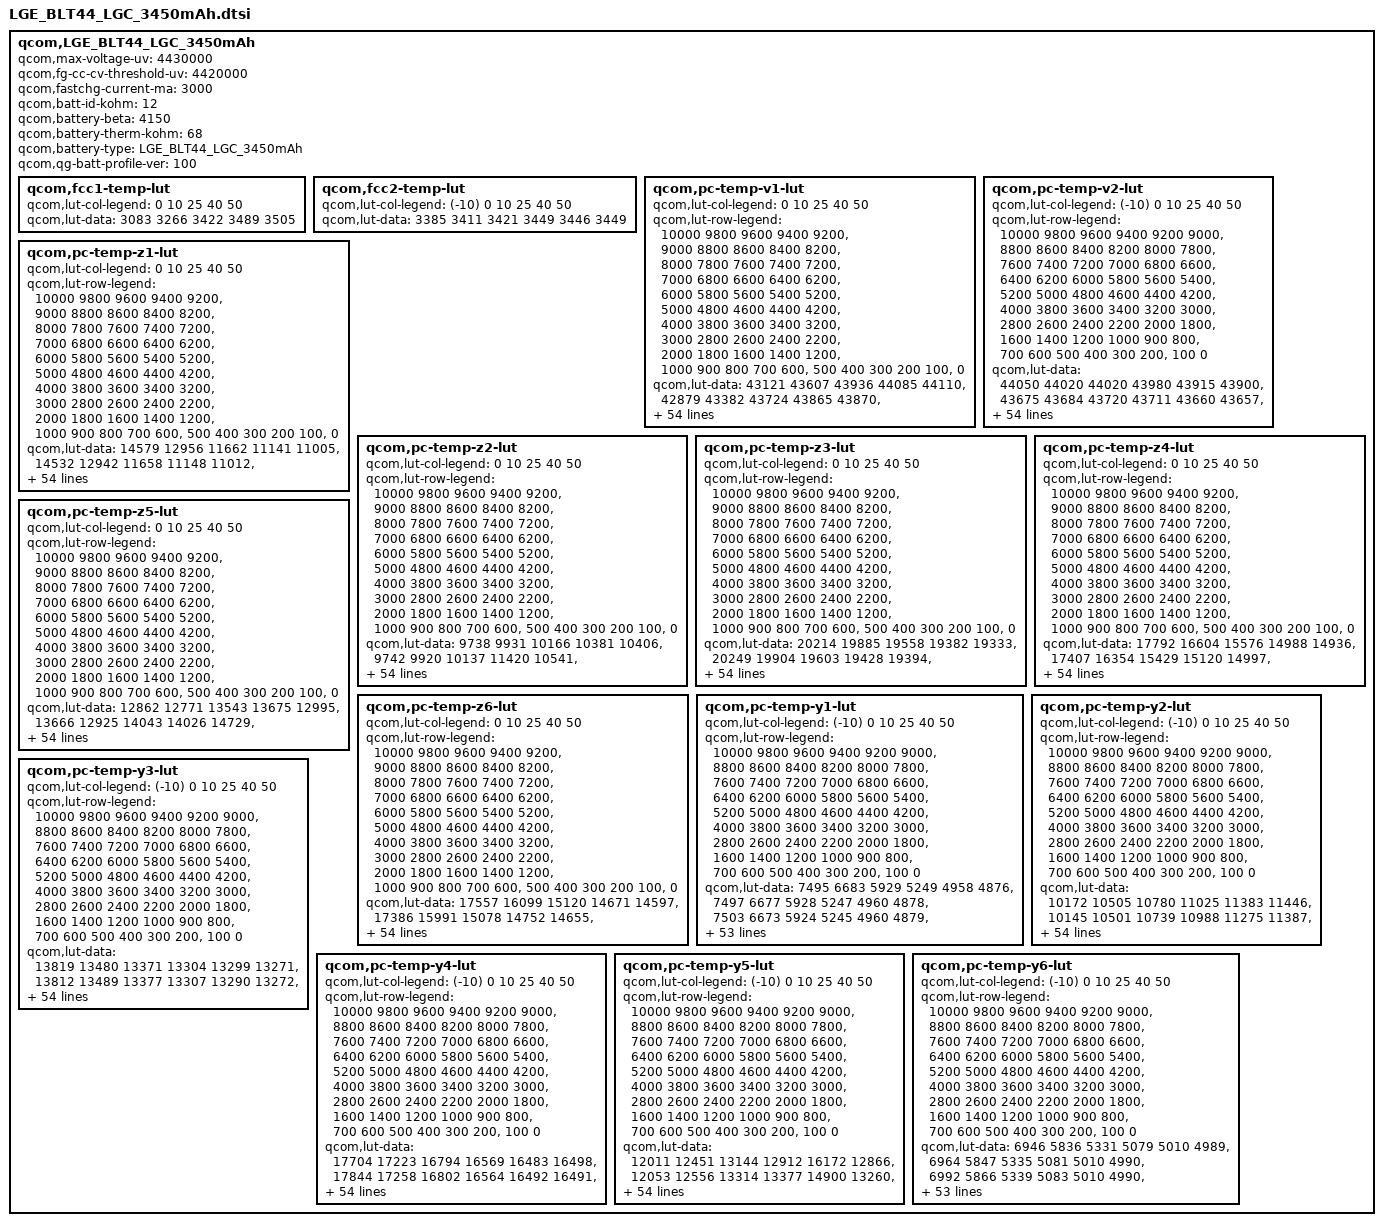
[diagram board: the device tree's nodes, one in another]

qcom,LGE_BLT44_LGC_3450mAh {
    /* 3748128_LGE_CV7ASlgc_3450mAh_averaged_MasterSlave_Dec13th2018 */
    qcom,max-voltage-uv = <4430000>;
    qcom,fg-cc-cv-threshold-uv = <4420000>;
    qcom,fastchg-current-ma = <3000>;
    qcom,batt-id-kohm = <12>;
    qcom,battery-beta = <4150>;
    qcom,battery-therm-kohm = <68>;
    qcom,battery-type = "LGE_BLT44_LGC_3450mAh";
    qcom,qg-batt-profile-ver = <100>;

	qcom,fcc1-temp-lut {
		qcom,lut-col-legend = <0 10 25 40 50>;
		qcom,lut-data = <3083 3266 3422 3489 3505>;
	};

	qcom,fcc2-temp-lut {
		qcom,lut-col-legend = <(-10) 0 10 25 40 50>;
		qcom,lut-data = <3385 3411 3421 3449 3446 3449>;
	};

	qcom,pc-temp-v1-lut {
		qcom,lut-col-legend = <0 10 25 40 50>;
		qcom,lut-row-legend = <10000 9800 9600 9400 9200>,
			<9000 8800 8600 8400 8200>,
			<8000 7800 7600 7400 7200>,
			<7000 6800 6600 6400 6200>,
			<6000 5800 5600 5400 5200>,
			<5000 4800 4600 4400 4200>,
			<4000 3800 3600 3400 3200>,
			<3000 2800 2600 2400 2200>,
			<2000 1800 1600 1400 1200>,
			<1000 900 800 700 600>,
			<500 400 300 200 100>,
			<0>;
		qcom,lut-data = <43121 43607 43936 44085 44110>,
			<42879 43382 43724 43865 43870>,
			<42643 43154 43503 43648 43652>,
			<42412 42922 43274 43426 43436>,
			<42188 42686 43038 43196 43211>,
			<41967 42449 42798 42960 42981>,
			<41752 42217 42557 42721 42746>,
			<41540 41986 42315 42479 42505>,
			<41334 41761 42077 42236 42262>,
			<41135 41539 41840 41994 42022>,
			<40941 41323 41608 41754 41784>,
			<40748 41113 41379 41520 41549>,
			<40548 40910 41156 41291 41318>,
			<40354 40712 40945 41068 41091>,
			<40176 40509 40740 40851 40872>,
			<40014 40309 40540 40640 40659>,
			<39863 40125 40341 40438 40454>,
			<39726 39958 40151 40241 40255>,
			<39598 39800 39976 40055 40066>,
			<39479 39647 39813 39892 39896>,
			<39364 39501 39648 39729 39730>,
			<39255 39358 39483 39524 39530>,
			<39150 39219 39309 39266 39285>,
			<39051 39082 39088 39047 39069>,
			<38956 38942 38827 38888 38907>,
			<38866 38791 38657 38755 38768>,
			<38781 38654 38574 38639 38642>,
			<38700 38549 38512 38537 38528>,
			<38622 38461 38446 38443 38425>,
			<38546 38390 38383 38351 38331>,
			<38475 38334 38321 38267 38245>,
			<38413 38287 38258 38195 38169>,
			<38359 38245 38198 38132 38100>,
			<38307 38209 38147 38075 38037>,
			<38261 38174 38102 38027 37985>,
			<38218 38139 38058 37981 37932>,
			<38171 38103 38018 37929 37865>,
			<38116 38058 37975 37874 37788>,
			<38053 37992 37910 37806 37710>,
			<37977 37908 37813 37720 37635>,
			<37874 37806 37702 37619 37550>,
			<37751 37675 37579 37504 37435>,
			<37602 37529 37442 37371 37295>,
			<37464 37366 37280 37209 37132>,
			<37359 37230 37146 37066 36992>,
			<37247 37147 37066 36984 36917>,
			<37200 37120 37044 36965 36902>,
			<37158 37096 37027 36952 36889>,
			<37112 37062 37003 36934 36870>,
			<37018 36997 36955 36878 36806>,
			<36768 36761 36703 36613 36514>,
			<36320 36298 36263 36164 36068>,
			<35731 35710 35682 35567 35480>,
			<34928 34890 34886 34739 34672>,
			<33556 33548 33630 33472 33430>,
			<30000 30000 30000 30000 30000>;
	};

	qcom,pc-temp-v2-lut {
		qcom,lut-col-legend = <(-10) 0 10 25 40 50>;
		qcom,lut-row-legend = <10000 9800 9600 9400 9200 9000>,
			<8800 8600 8400 8200 8000 7800>,
			<7600 7400 7200 7000 6800 6600>,
			<6400 6200 6000 5800 5600 5400>,
			<5200 5000 4800 4600 4400 4200>,
			<4000 3800 3600 3400 3200 3000>,
			<2800 2600 2400 2200 2000 1800>,
			<1600 1400 1200 1000 900 800>,
			<700 600 500 400 300 200>,
			<100 0>;
		qcom,lut-data = <44050 44020 44020 43980 43915 43900>,
			<43675 43684 43720 43711 43660 43657>,
			<43333 43371 43436 43451 43412 43419>,
			<43030 43086 43170 43204 43171 43184>,
			<42762 42828 42922 42968 42938 42955>,
			<42509 42577 42679 42733 42705 42723>,
			<42267 42318 42431 42491 42467 42486>,
			<42032 42061 42185 42248 42228 42246>,
			<41767 41818 41943 42009 41991 42009>,
			<41451 41587 41705 41772 41754 41772>,
			<41159 41360 41472 41539 41522 41540>,
			<40959 41133 41245 41308 41294 41313>,
			<40796 40907 41022 41082 41070 41090>,
			<40581 40681 40808 40865 40853 40874>,
			<40248 40455 40603 40656 40642 40662>,
			<39903 40229 40399 40452 40438 40457>,
			<39647 39997 40196 40249 40240 40258>,
			<39430 39764 39992 40050 40050 40066>,
			<39226 39549 39785 39866 39871 39886>,
			<39031 39349 39570 39699 39708 39721>,
			<38839 39159 39357 39517 39529 39542>,
			<38623 38967 39149 39278 39294 39311>,
			<38382 38779 38948 39026 39042 39067>,
			<38217 38601 38773 38836 38852 38877>,
			<38134 38430 38622 38686 38703 38722>,
			<38073 38275 38488 38557 38574 38588>,
			<38013 38141 38368 38443 38460 38472>,
			<37956 38022 38260 38340 38357 38368>,
			<37900 37941 38159 38245 38262 38272>,
			<37843 37892 38057 38156 38172 38181>,
			<37786 37851 37967 38075 38091 38098>,
			<37730 37805 37894 38002 38020 38025>,
			<37676 37758 37833 37933 37954 37955>,
			<37621 37710 37782 37866 37886 37886>,
			<37566 37663 37744 37798 37818 37818>,
			<37512 37616 37708 37731 37743 37739>,
			<37454 37566 37667 37668 37652 37629>,
			<37395 37514 37624 37605 37552 37505>,
			<37333 37452 37568 37535 37464 37407>,
			<37266 37374 37491 37459 37388 37329>,
			<37196 37281 37396 37371 37304 37245>,
			<37122 37175 37284 37255 37193 37134>,
			<37045 37050 37147 37120 37064 37007>,
			<36959 36930 36984 36954 36894 36841>,
			<36856 36816 36835 36865 36824 36772>,
			<36745 36707 36755 36829 36802 36750>,
			<36676 36659 36724 36813 36783 36737>,
			<36591 36612 36681 36779 36756 36710>,
			<36487 36559 36630 36717 36692 36649>,
			<36343 36469 36534 36519 36481 36437>,
			<36096 36227 36280 36100 36066 36034>,
			<35710 35751 35796 35555 35523 35505>,
			<35130 35102 35151 34857 34863 34858>,
			<34343 34221 34274 33935 34074 34108>,
			<33401 33106 32990 32871 32870 32902>,
			<28079 28204 28388 29298 27603 28388>;
	};

	qcom,pc-temp-z1-lut {
		qcom,lut-col-legend = <0 10 25 40 50>;
		qcom,lut-row-legend = <10000 9800 9600 9400 9200>,
			<9000 8800 8600 8400 8200>,
			<8000 7800 7600 7400 7200>,
			<7000 6800 6600 6400 6200>,
			<6000 5800 5600 5400 5200>,
			<5000 4800 4600 4400 4200>,
			<4000 3800 3600 3400 3200>,
			<3000 2800 2600 2400 2200>,
			<2000 1800 1600 1400 1200>,
			<1000 900 800 700 600>,
			<500 400 300 200 100>,
			<0>;
		qcom,lut-data = <14579 12956 11662 11141 11005>,
			<14532 12942 11658 11148 11012>,
			<14488 12928 11653 11149 11015>,
			<14450 12915 11646 11150 11016>,
			<14405 12896 11635 11149 11017>,
			<14372 12878 11627 11146 11018>,
			<14360 12867 11621 11145 11018>,
			<14357 12857 11617 11143 11018>,
			<14357 12847 11615 11142 11018>,
			<14352 12829 11613 11141 11018>,
			<14337 12811 11612 11141 11018>,
			<14323 12808 11610 11141 11019>,
			<14314 12811 11609 11141 11019>,
			<14306 12814 11609 11142 11020>,
			<14288 12810 11609 11142 11021>,
			<14220 12804 11610 11143 11023>,
			<14149 12805 11612 11144 11025>,
			<14128 12812 11614 11146 11026>,
			<14121 12822 11617 11147 11028>,
			<14114 12833 11620 11150 11031>,
			<14095 12848 11624 11152 11033>,
			<14057 12859 11629 11155 11034>,
			<14035 12867 11636 11157 11035>,
			<14039 12873 11640 11159 11036>,
			<14048 12876 11645 11162 11040>,
			<14055 12882 11650 11166 11044>,
			<14053 12891 11655 11171 11048>,
			<14048 12898 11661 11176 11052>,
			<14045 12906 11667 11180 11055>,
			<14038 12914 11672 11185 11059>,
			<14030 12924 11678 11189 11062>,
			<14036 12934 11685 11193 11065>,
			<14068 12941 11692 11196 11068>,
			<14093 12945 11698 11199 11071>,
			<14090 12949 11703 11202 11073>,
			<14077 12956 11710 11206 11076>,
			<14067 12969 11718 11209 11079>,
			<14073 12980 11727 11213 11082>,
			<14089 12986 11734 11216 11084>,
			<14097 12993 11740 11218 11085>,
			<14108 13005 11746 11220 11087>,
			<14117 13024 11753 11223 11090>,
			<14104 13028 11759 11226 11092>,
			<14081 13023 11763 11230 11095>,
			<14041 13016 11770 11234 11098>,
			<14034 13016 11776 11241 11100>,
			<14032 13028 11782 11240 11101>,
			<14060 13033 11780 11242 11103>,
			<14036 13019 11788 11243 11105>,
			<14067 13038 11794 11247 11107>,
			<14066 13067 11808 11252 11112>,
			<14052 13068 11819 11261 11121>,
			<14062 13076 11844 11276 11132>,
			<14080 13096 11883 11299 11151>,
			<14080 13096 11883 11299 11151>,
			<14080 13096 11883 11299 11151>;
	};

	qcom,pc-temp-z2-lut {
		qcom,lut-col-legend = <0 10 25 40 50>;
		qcom,lut-row-legend = <10000 9800 9600 9400 9200>,
			<9000 8800 8600 8400 8200>,
			<8000 7800 7600 7400 7200>,
			<7000 6800 6600 6400 6200>,
			<6000 5800 5600 5400 5200>,
			<5000 4800 4600 4400 4200>,
			<4000 3800 3600 3400 3200>,
			<3000 2800 2600 2400 2200>,
			<2000 1800 1600 1400 1200>,
			<1000 900 800 700 600>,
			<500 400 300 200 100>,
			<0>;
		qcom,lut-data = <9738 9931 10166 10381 10406>,
			<9742 9920 10137 11420 10541>,
			<9742 9909 10107 11150 10561>,
			<9738 9901 10070 10807 10583>,
			<9728 9894 10030 10551 10574>,
			<9718 9887 10010 10327 10543>,
			<9712 9876 9999 10278 10533>,
			<9707 9863 9994 10310 10548>,
			<9703 9854 10003 10354 10562>,
			<9695 9848 10029 10457 10517>,
			<9687 9844 10051 10606 10409>,
			<9682 9845 10063 10628 10377>,
			<9678 9851 10081 10517 10397>,
			<9675 9855 10165 10442 10422>,
			<9674 9852 10339 10543 10445>,
			<9672 9846 10436 10704 10473>,
			<9672 9844 10475 10751 10495>,
			<9672 9844 10496 10771 10514>,
			<9676 9845 10443 10786 10536>,
			<9682 9849 10295 10683 10562>,
			<9688 9861 10234 10531 10599>,
			<9696 9875 10248 10538 10674>,
			<9705 9889 10264 10635 10848>,
			<9715 9905 10257 10683 10944>,
			<9726 9924 10232 10546 10859>,
			<9734 9949 10220 10370 10739>,
			<9739 9967 10222 10423 10730>,
			<9743 9971 10225 10695 10761>,
			<9748 9972 10241 10824 10776>,
			<9756 9972 10286 10679 10709>,
			<9764 9972 10308 10508 10629>,
			<9772 9972 10295 10497 10634>,
			<9779 9973 10279 10519 10689>,
			<9787 9976 10275 10549 10759>,
			<9794 9981 10273 10611 10870>,
			<9801 9987 10274 10681 10989>,
			<9809 9994 10279 10731 11082>,
			<9818 10003 10289 10775 11167>,
			<9829 10015 10307 10802 11190>,
			<9840 10028 10341 10817 11172>,
			<9854 10036 10359 10829 11152>,
			<9872 10040 10354 10838 11134>,
			<9907 10047 10351 10847 11116>,
			<9830 10064 10362 10857 11039>,
			<9223 10215 10425 10873 11010>,
			<9248 10250 10456 10895 11027>,
			<9251 10247 10452 10823 11036>,
			<9269 10233 10445 10761 11101>,
			<9309 10254 10453 10785 11131>,
			<9316 10294 10517 10885 11201>,
			<9287 10244 10585 10804 10790>,
			<9252 10142 10507 10671 10658>,
			<9224 10009 10369 10503 10579>,
			<9192 9946 10280 10469 10517>,
			<9192 9946 10280 10469 10517>,
			<9192 9946 10280 10469 10517>;
	};

	qcom,pc-temp-z3-lut {
		qcom,lut-col-legend = <0 10 25 40 50>;
		qcom,lut-row-legend = <10000 9800 9600 9400 9200>,
			<9000 8800 8600 8400 8200>,
			<8000 7800 7600 7400 7200>,
			<7000 6800 6600 6400 6200>,
			<6000 5800 5600 5400 5200>,
			<5000 4800 4600 4400 4200>,
			<4000 3800 3600 3400 3200>,
			<3000 2800 2600 2400 2200>,
			<2000 1800 1600 1400 1200>,
			<1000 900 800 700 600>,
			<500 400 300 200 100>,
			<0>;
		qcom,lut-data = <20214 19885 19558 19382 19333>,
			<20249 19904 19603 19428 19394>,
			<20273 19914 19636 19476 19423>,
			<20277 19913 19658 19513 19438>,
			<20277 19899 19675 19514 19439>,
			<20277 19885 19679 19511 19437>,
			<20277 19876 19671 19504 19433>,
			<20278 19868 19659 19484 19424>,
			<20278 19862 19640 19467 19413>,
			<20278 19857 19613 19472 19400>,
			<20278 19851 19595 19486 19383>,
			<20278 19843 19582 19482 19373>,
			<20282 19830 19575 19448 19367>,
			<20288 19822 19581 19424 19362>,
			<20290 19823 19598 19430 19356>,
			<20287 19826 19605 19442 19350>,
			<20282 19827 19600 19441 19347>,
			<20275 19827 19591 19432 19345>,
			<20262 19827 19569 19420 19344>,
			<20246 19825 19528 19402 19343>,
			<20230 19820 19512 19386 19342>,
			<20214 19817 19519 19393 19347>,
			<20197 19818 19531 19433 19373>,
			<20178 19820 19545 19454 19389>,
			<20159 19823 19565 19420 19361>,
			<20146 19836 19573 19375 19322>,
			<20139 19847 19552 19376 19331>,
			<20133 19845 19525 19402 19387>,
			<20128 19835 19517 19421 19416>,
			<20123 19826 19512 19438 19411>,
			<20118 19817 19510 19453 19402>,
			<20110 19807 19528 19451 19393>,
			<20096 19797 19549 19438 19383>,
			<20081 19786 19551 19426 19376>,
			<20070 19775 19545 19415 19370>,
			<20061 19768 19539 19408 19366>,
			<20050 19761 19530 19408 19367>,
			<20034 19754 19521 19408 19371>,
			<20014 19745 19517 19408 19372>,
			<19994 19736 19515 19404 19364>,
			<19975 19724 19512 19398 19355>,
			<19950 19711 19507 19388 19352>,
			<19914 19697 19501 19379 19350>,
			<19771 19681 19492 19379 19341>,
			<19304 19603 19463 19374 19335>,
			<19293 19555 19445 19359 19335>,
			<19292 19470 19436 19356 19324>,
			<19285 19371 19425 19343 19321>,
			<19279 19345 19428 19339 19315>,
			<19279 19330 19389 19335 19315>,
			<19284 19351 19401 19342 19347>,
			<19292 19373 19389 19355 19349>,
			<19298 19384 19412 19365 19353>,
			<19336 19493 19423 19382 19356>,
			<19336 19493 19423 19382 19356>,
			<19336 19493 19423 19382 19356>;
	};

	qcom,pc-temp-z4-lut {
		qcom,lut-col-legend = <0 10 25 40 50>;
		qcom,lut-row-legend = <10000 9800 9600 9400 9200>,
			<9000 8800 8600 8400 8200>,
			<8000 7800 7600 7400 7200>,
			<7000 6800 6600 6400 6200>,
			<6000 5800 5600 5400 5200>,
			<5000 4800 4600 4400 4200>,
			<4000 3800 3600 3400 3200>,
			<3000 2800 2600 2400 2200>,
			<2000 1800 1600 1400 1200>,
			<1000 900 800 700 600>,
			<500 400 300 200 100>,
			<0>;
		qcom,lut-data = <17792 16604 15576 14988 14936>,
			<17407 16354 15429 15120 14997>,
			<17068 16134 15303 15044 14965>,
			<16781 15946 15199 14961 14916>,
			<16527 15781 15109 14923 14876>,
			<16314 15642 15038 14896 14837>,
			<16145 15530 14978 14875 14820>,
			<16002 15434 14935 14860 14814>,
			<15884 15353 14914 14845 14811>,
			<15782 15284 14900 14814 14811>,
			<15694 15224 14886 14778 14812>,
			<15625 15167 14874 14769 14811>,
			<15572 15114 14859 14788 14803>,
			<15527 15073 14825 14799 14792>,
			<15484 15049 14772 14775 14783>,
			<15442 15031 14747 14737 14774>,
			<15404 15010 14739 14727 14763>,
			<15366 14983 14735 14724 14752>,
			<15331 14959 14748 14723 14741>,
			<15297 14941 14785 14728 14732>,
			<15265 14926 14802 14739 14724>,
			<15235 14920 14803 14757 14730>,
			<15209 14920 14803 14797 14773>,
			<15189 14920 14839 14843 14824>,
			<15172 14923 14944 14903 14879>,
			<15158 14946 14992 14953 14925>,
			<15147 14973 14987 14947 14911>,
			<15137 14987 14977 14899 14830>,
			<15128 14999 14963 14853 14776>,
			<15120 15004 14940 14812 14760>,
			<15111 14998 14913 14778 14750>,
			<15103 14987 14875 14766 14741>,
			<15095 14975 14839 14759 14732>,
			<15085 14961 14824 14756 14728>,
			<15072 14945 14815 14753 14727>,
			<15052 14930 14811 14752 14726>,
			<15029 14916 14809 14755 14738>,
			<15000 14902 14807 14764 14768>,
			<14966 14888 14809 14773 14778>,
			<14937 14875 14819 14780 14772>,
			<14915 14867 14824 14785 14763>,
			<14896 14863 14813 14782 14750>,
			<14879 14851 14798 14773 14738>,
			<14925 14821 14787 14766 14744>,
			<15262 14762 14754 14751 14738>,
			<15252 14766 14720 14716 14701>,
			<15241 14843 14707 14701 14690>,
			<15233 14939 14698 14690 14668>,
			<15217 14954 14682 14674 14655>,
			<15195 14959 14718 14682 14667>,
			<15207 14943 14735 14700 14651>,
			<15251 14958 14753 14685 14648>,
			<15292 14963 14734 14674 14646>,
			<15305 14875 14732 14665 14655>,
			<15305 14875 14732 14665 14655>,
			<15305 14875 14732 14665 14655>;
	};

	qcom,pc-temp-z5-lut {
		qcom,lut-col-legend = <0 10 25 40 50>;
		qcom,lut-row-legend = <10000 9800 9600 9400 9200>,
			<9000 8800 8600 8400 8200>,
			<8000 7800 7600 7400 7200>,
			<7000 6800 6600 6400 6200>,
			<6000 5800 5600 5400 5200>,
			<5000 4800 4600 4400 4200>,
			<4000 3800 3600 3400 3200>,
			<3000 2800 2600 2400 2200>,
			<2000 1800 1600 1400 1200>,
			<1000 900 800 700 600>,
			<500 400 300 200 100>,
			<0>;
		qcom,lut-data = <12862 12771 13543 13675 12995>,
			<13666 12925 14043 14026 14729>,
			<14370 13098 14515 15203 15535>,
			<14955 13291 14974 16160 16093>,
			<15460 13515 15403 16316 16496>,
			<15889 13732 15747 16392 16811>,
			<16259 13924 16116 16389 16884>,
			<16588 14113 16353 16242 16605>,
			<16831 14275 16318 16128 16240>,
			<16975 14416 16208 17338 15800>,
			<17082 14561 16176 19595 15129>,
			<17207 14730 16319 19783 14852>,
			<17384 14944 16613 17532 14829>,
			<17575 15184 17758 15955 14845>,
			<17729 15457 20167 17659 14847>,
			<17845 15800 21553 20467 14886>,
			<17958 16228 22154 21028 15027>,
			<18099 16811 22477 20472 15378>,
			<18272 17543 21640 19729 15825>,
			<18466 18408 19229 18569 16243>,
			<18690 19478 18265 17575 16799>,
			<18949 20710 19612 20186 18538>,
			<19190 22085 21875 30443 23655>,
			<19381 23702 24906 35888 26580>,
			<19555 25866 29315 27872 21609>,
			<19754 29475 31018 17311 14643>,
			<19992 32111 26725 15639 14133>,
			<20283 31837 21203 15696 16273>,
			<20680 30463 19274 16116 18017>,
			<21369 29077 18179 17986 18812>,
			<21999 27819 17854 20304 19490>,
			<22201 26632 19676 21546 20395>,
			<22223 25758 22348 22478 21458>,
			<22245 24977 23879 23155 22453>,
			<22373 24546 25108 23682 23688>,
			<22558 24563 25589 24055 24611>,
			<22715 24671 25288 24255 24541>,
			<23152 24861 24815 24397 23933>,
			<23964 25780 24551 24328 23093>,
			<24657 26808 24364 22650 20833>,
			<25985 26745 24240 20527 18758>,
			<26974 25860 24250 19200 18414>,
			<26112 25837 24193 18335 18402>,
			<22181 26745 23335 18307 16940>,
			<11073 26372 23266 18378 16669>,
			<11001 20525 23358 19191 18605>,
			<10972 15737 22692 19735 18014>,
			<10923 12078 20889 18915 19824>,
			<10923 11736 22284 19835 21196>,
			<10932 11603 17809 18310 18479>,
			<10995 11951 16174 16063 23267>,
			<10998 12001 14811 17238 24104>,
			<10883 12094 16588 19250 27747>,
			<11376 16122 17722 26810 30139>,
			<11376 16122 17722 26810 30139>,
			<11376 16122 17722 26810 30139>;
	};

	qcom,pc-temp-z6-lut {
		qcom,lut-col-legend = <0 10 25 40 50>;
		qcom,lut-row-legend = <10000 9800 9600 9400 9200>,
			<9000 8800 8600 8400 8200>,
			<8000 7800 7600 7400 7200>,
			<7000 6800 6600 6400 6200>,
			<6000 5800 5600 5400 5200>,
			<5000 4800 4600 4400 4200>,
			<4000 3800 3600 3400 3200>,
			<3000 2800 2600 2400 2200>,
			<2000 1800 1600 1400 1200>,
			<1000 900 800 700 600>,
			<500 400 300 200 100>,
			<0>;
		qcom,lut-data = <17557 16099 15120 14671 14597>,
			<17386 15991 15078 14752 14655>,
			<17232 15892 15039 14743 14652>,
			<17097 15801 15005 14731 14646>,
			<16975 15715 14973 14719 14636>,
			<16871 15641 14942 14704 14618>,
			<16787 15582 14913 14688 14605>,
			<16716 15532 14886 14671 14598>,
			<16655 15490 14864 14656 14591>,
			<16601 15454 14844 14647 14584>,
			<16553 15422 14829 14639 14576>,
			<16511 15391 14817 14630 14569>,
			<16476 15359 14806 14621 14562>,
			<16445 15338 14794 14612 14555>,
			<16415 15330 14782 14604 14548>,
			<16386 15325 14773 14596 14540>,
			<16358 15319 14767 14589 14534>,
			<16329 15311 14761 14583 14528>,
			<16299 15302 14756 14577 14523>,
			<16269 15295 14750 14571 14518>,
			<16239 15288 14748 14567 14514>,
			<16209 15286 14752 14576 14520>,
			<16184 15288 14759 14618 14556>,
			<16161 15293 14785 14645 14582>,
			<16142 15301 14840 14651 14589>,
			<16133 15321 14864 14654 14592>,
			<16131 15339 14853 14652 14592>,
			<16130 15344 14837 14646 14587>,
			<16128 15347 14825 14639 14581>,
			<16125 15348 14814 14632 14573>,
			<16121 15344 14806 14625 14563>,
			<16116 15338 14800 14617 14555>,
			<16107 15331 14795 14609 14546>,
			<16099 15320 14790 14601 14540>,
			<16094 15311 14785 14595 14536>,
			<16090 15307 14781 14590 14533>,
			<16084 15304 14776 14592 14539>,
			<16074 15300 14773 14597 14554>,
			<16060 15293 14773 14599 14559>,
			<16046 15285 14777 14600 14553>,
			<16031 15279 14780 14600 14544>,
			<16014 15274 14774 14595 14537>,
			<15995 15266 14765 14586 14531>,
			<15951 15250 14757 14583 14530>,
			<15855 15188 14730 14575 14524>,
			<15850 15169 14707 14552 14508>,
			<15848 15159 14698 14545 14498>,
			<15846 15152 14689 14533 14487>,
			<15844 15149 14685 14524 14478>,
			<15844 15148 14683 14526 14483>,
			<15857 15162 14699 14539 14494>,
			<15888 15191 14706 14541 14496>,
			<15918 15212 14716 14545 14500>,
			<15969 15252 14732 14555 14510>,
			<15969 15252 14732 14555 14510>,
			<15969 15252 14732 14555 14510>;
	};

	qcom,pc-temp-y1-lut {
		qcom,lut-col-legend = <(-10) 0 10 25 40 50>;
		qcom,lut-row-legend = <10000 9800 9600 9400 9200 9000>,
			<8800 8600 8400 8200 8000 7800>,
			<7600 7400 7200 7000 6800 6600>,
			<6400 6200 6000 5800 5600 5400>,
			<5200 5000 4800 4600 4400 4200>,
			<4000 3800 3600 3400 3200 3000>,
			<2800 2600 2400 2200 2000 1800>,
			<1600 1400 1200 1000 900 800>,
			<700 600 500 400 300 200>,
			<100 0>;
		qcom,lut-data = <7495 6683 5929 5249 4958 4876>,
			<7497 6677 5928 5247 4960 4878>,
			<7503 6673 5924 5245 4960 4879>,
			<7510 6671 5920 5243 4960 4880>,
			<7516 6670 5916 5241 4960 4881>,
			<7518 6669 5915 5241 4959 4881>,
			<7518 6666 5915 5241 4958 4880>,
			<7518 6662 5916 5241 4955 4879>,
			<7517 6663 5915 5240 4955 4879>,
			<7509 6686 5910 5236 4955 4878>,
			<7499 6704 5906 5234 4955 4878>,
			<7504 6693 5907 5234 4954 4878>,
			<7520 6669 5907 5234 4954 4879>,
			<7527 6664 5910 5234 4954 4879>,
			<7535 6674 5924 5234 4954 4880>,
			<7545 6683 5936 5234 4954 4880>,
			<7536 6688 5936 5234 4955 4881>,
			<7505 6691 5935 5234 4956 4882>,
			<7490 6691 5933 5235 4956 4883>,
			<7503 6683 5929 5239 4957 4884>,
			<7519 6675 5927 5242 4958 4885>,
			<7526 6680 5931 5242 4959 4885>,
			<7539 6693 5941 5241 4961 4886>,
			<7545 6697 5945 5242 4962 4887>,
			<7541 6691 5945 5246 4963 4887>,
			<7535 6685 5945 5250 4964 4888>,
			<7525 6689 5947 5254 4965 4889>,
			<7504 6699 5949 5257 4966 4891>,
			<7491 6702 5953 5259 4968 4892>,
			<7500 6692 5969 5262 4970 4893>,
			<7516 6681 5984 5264 4973 4894>,
			<7519 6680 5985 5267 4973 4896>,
			<7504 6680 5978 5270 4974 4898>,
			<7492 6681 5975 5272 4975 4900>,
			<7493 6689 5976 5274 4977 4901>,
			<7502 6698 5977 5275 4979 4902>,
			<7506 6698 5983 5276 4981 4904>,
			<7494 6698 5994 5278 4983 4905>,
			<7477 6699 6002 5280 4985 4907>,
			<7462 6690 6007 5283 4987 4908>,
			<7447 6678 6010 5286 4989 4909>,
			<7440 6677 6009 5291 4991 4911>,
			<7439 6681 6006 5296 4993 4913>,
			<7441 6694 6016 5301 4995 4914>,
			<7465 6717 6029 5305 4996 4916>,
			<7455 6726 6024 5306 4998 4917>,
			<7450 6717 6026 5308 5000 4919>,
			<7509 6737 6020 5317 5001 4919>,
			<7510 6718 6025 5326 5004 4919>,
			<7528 6721 6037 5330 5006 4922>,
			<7570 6757 6034 5345 5013 4929>,
			<7663 6752 6043 5371 5026 4936>,
			<7802 6836 6108 5398 5042 4948>,
			<7894 6948 6135 5439 5062 4965>,
			<7894 6948 6135 5439 5062 4965>,
			<7894 6948 6135 5439 5062 4965>;
	};

	qcom,pc-temp-y2-lut {
		qcom,lut-col-legend = <(-10) 0 10 25 40 50>;
		qcom,lut-row-legend = <10000 9800 9600 9400 9200 9000>,
			<8800 8600 8400 8200 8000 7800>,
			<7600 7400 7200 7000 6800 6600>,
			<6400 6200 6000 5800 5600 5400>,
			<5200 5000 4800 4600 4400 4200>,
			<4000 3800 3600 3400 3200 3000>,
			<2800 2600 2400 2200 2000 1800>,
			<1600 1400 1200 1000 900 800>,
			<700 600 500 400 300 200>,
			<100 0>;
		qcom,lut-data = <10172 10505 10780 11025 11383 11446>,
			<10145 10501 10739 10988 11275 11387>,
			<10140 10496 10696 10952 11163 11329>,
			<10152 10492 10656 10919 11063 11273>,
			<10175 10487 10622 10890 10991 11220>,
			<10205 10483 10597 10867 10963 11170>,
			<10258 10478 10579 10849 10983 11113>,
			<10321 10473 10566 10835 11017 11065>,
			<10336 10473 10560 10820 11030 11060>,
			<10326 10481 10556 10803 11035 11077>,
			<10317 10493 10555 10794 11037 11088>,
			<10333 10516 10561 10802 11029 11096>,
			<10373 10550 10578 10813 11014 11110>,
			<10388 10571 10597 10813 11002 11106>,
			<10250 10584 10623 10800 10988 11077>,
			<10096 10595 10651 10792 10985 11058>,
			<9995 10607 10680 10815 11030 11061>,
			<9774 10618 10710 10862 11105 11072>,
			<9678 10628 10731 10902 11160 11111>,
			<9674 10636 10748 10940 11205 11240>,
			<9672 10642 10762 10971 11247 11325>,
			<9668 10648 10774 10990 11301 11324>,
			<9664 10653 10785 11007 11350 11317>,
			<9661 10654 10795 11030 11359 11336>,
			<9660 10634 10806 11065 11354 11422>,
			<9659 10614 10817 11090 11351 11509>,
			<9658 10616 10830 11101 11395 11569>,
			<9657 10627 10842 11110 11469 11628>,
			<9656 10631 10849 11118 11499 11680>,
			<9655 10597 10854 11126 11516 11745>,
			<9655 10527 10858 11133 11540 11818>,
			<9655 10333 10858 11143 11614 11901>,
			<9655 9915 10858 11152 11705 11988>,
			<9655 9705 10854 11147 11714 12057>,
			<9655 9683 10816 11108 11656 12123>,
			<9655 9672 10759 11078 11588 12153>,
			<9655 9666 10710 11071 11528 12063>,
			<9655 9662 10658 11067 11473 11905>,
			<9655 9660 10604 11061 11457 11819>,
			<9655 9658 10551 11053 11479 11760>,
			<9655 9657 10494 11040 11493 11733>,
			<9655 9656 10432 11015 11441 11753>,
			<9654 9655 10353 10977 11380 11773>,
			<9654 9655 10089 10909 11369 11714>,
			<9654 9654 9758 10848 11309 11620>,
			<9654 9654 9708 10856 11274 11489>,
			<9653 9653 9713 10826 11298 11461>,
			<9653 9653 9680 10805 11232 11410>,
			<9653 9653 9667 10746 11228 11327>,
			<9657 9654 9660 10663 11094 11224>,
			<9659 9658 9657 10591 11034 11152>,
			<9661 9662 9654 10506 10919 11044>,
			<9662 9668 9654 10426 10832 10899>,
			<9655 9658 9666 10323 10783 10903>,
			<9655 9658 9666 10323 10783 10903>,
			<9655 9658 9666 10323 10783 10903>;
	};

	qcom,pc-temp-y3-lut {
		qcom,lut-col-legend = <(-10) 0 10 25 40 50>;
		qcom,lut-row-legend = <10000 9800 9600 9400 9200 9000>,
			<8800 8600 8400 8200 8000 7800>,
			<7600 7400 7200 7000 6800 6600>,
			<6400 6200 6000 5800 5600 5400>,
			<5200 5000 4800 4600 4400 4200>,
			<4000 3800 3600 3400 3200 3000>,
			<2800 2600 2400 2200 2000 1800>,
			<1600 1400 1200 1000 900 800>,
			<700 600 500 400 300 200>,
			<100 0>;
		qcom,lut-data = <13819 13480 13371 13304 13299 13271>,
			<13812 13489 13377 13307 13290 13272>,
			<13809 13498 13383 13311 13284 13274>,
			<13809 13507 13389 13315 13282 13275>,
			<13811 13514 13393 13318 13281 13277>,
			<13815 13520 13397 13319 13282 13278>,
			<13825 13524 13400 13318 13286 13279>,
			<13839 13527 13403 13317 13292 13279>,
			<13833 13533 13405 13317 13294 13280>,
			<13735 13546 13406 13319 13295 13279>,
			<13649 13554 13407 13320 13295 13280>,
			<13656 13541 13407 13319 13294 13283>,
			<13681 13514 13406 13317 13293 13288>,
			<13688 13502 13406 13318 13293 13289>,
			<13668 13500 13409 13326 13292 13288>,
			<13647 13497 13411 13331 13291 13286>,
			<13647 13491 13410 13331 13295 13285>,
			<13654 13482 13406 13331 13301 13284>,
			<13662 13473 13402 13332 13305 13284>,
			<13673 13465 13396 13335 13307 13289>,
			<13681 13456 13388 13337 13308 13292>,
			<13671 13446 13380 13330 13302 13288>,
			<13629 13435 13372 13318 13292 13282>,
			<13606 13426 13367 13313 13288 13279>,
			<13636 13419 13364 13311 13286 13276>,
			<13698 13411 13362 13309 13285 13275>,
			<13772 13395 13360 13308 13285 13276>,
			<13876 13372 13359 13308 13284 13277>,
			<13993 13364 13358 13308 13284 13277>,
			<14119 13372 13354 13308 13282 13277>,
			<14252 13387 13350 13308 13281 13277>,
			<14372 13402 13348 13309 13283 13278>,
			<14483 13423 13347 13310 13285 13278>,
			<14584 13449 13347 13309 13285 13279>,
			<14675 13491 13353 13307 13285 13278>,
			<14758 13546 13362 13306 13284 13278>,
			<14836 13611 13372 13307 13283 13275>,
			<14909 13694 13383 13308 13281 13272>,
			<14980 13792 13392 13310 13281 13271>,
			<15052 13912 13399 13312 13282 13271>,
			<15123 14057 13406 13313 13283 13272>,
			<15202 14231 13412 13313 13283 13273>,
			<15289 14446 13416 13313 13284 13274>,
			<15404 14679 13421 13317 13281 13274>,
			<15579 14924 13438 13318 13283 13275>,
			<15856 15141 13498 13319 13289 13279>,
			<15922 15106 13495 13327 13289 13285>,
			<15975 15311 13564 13334 13291 13285>,
			<16380 15559 13679 13343 13294 13290>,
			<16948 15844 13835 13346 13297 13282>,
			<18126 16170 14124 13358 13301 13289>,
			<20479 16951 14630 13381 13305 13291>,
			<24865 19774 15413 13414 13311 13295>,
			<30522 23445 16566 13496 13322 13303>,
			<30522 23445 16566 13496 13322 13303>,
			<30522 23445 16566 13496 13322 13303>;
	};

	qcom,pc-temp-y4-lut {
		qcom,lut-col-legend = <(-10) 0 10 25 40 50>;
		qcom,lut-row-legend = <10000 9800 9600 9400 9200 9000>,
			<8800 8600 8400 8200 8000 7800>,
			<7600 7400 7200 7000 6800 6600>,
			<6400 6200 6000 5800 5600 5400>,
			<5200 5000 4800 4600 4400 4200>,
			<4000 3800 3600 3400 3200 3000>,
			<2800 2600 2400 2200 2000 1800>,
			<1600 1400 1200 1000 900 800>,
			<700 600 500 400 300 200>,
			<100 0>;
		qcom,lut-data = <17704 17223 16794 16569 16483 16498>,
			<17844 17258 16802 16564 16492 16491>,
			<18037 17332 16812 16562 16499 16486>,
			<18237 17418 16823 16561 16505 16484>,
			<18397 17492 16833 16561 16508 16483>,
			<18469 17526 16838 16563 16509 16483>,
			<18452 17528 16839 16568 16506 16484>,
			<18417 17529 16840 16578 16500 16487>,
			<18412 17528 16843 16585 16500 16491>,
			<18462 17521 16853 16590 16506 16498>,
			<18505 17515 16865 16597 16513 16502>,
			<18494 17551 16880 16610 16522 16502>,
			<18450 17621 16899 16627 16533 16502>,
			<18379 17637 16925 16638 16544 16505>,
			<18128 17594 16967 16646 16558 16516>,
			<17865 17531 16999 16657 16570 16530>,
			<17776 17460 17007 16677 16576 16543>,
			<17731 17376 17012 16707 16583 16557>,
			<17667 17312 17009 16740 16598 16573>,
			<17544 17268 16968 16783 16637 16593>,
			<17400 17224 16911 16805 16661 16603>,
			<17269 17164 16852 16735 16622 16578>,
			<17134 17091 16788 16619 16553 16533>,
			<17076 17012 16749 16576 16523 16509>,
			<17082 16914 16726 16558 16507 16494>,
			<17094 16830 16709 16551 16501 16487>,
			<17108 16790 16699 16554 16503 16488>,
			<17131 16757 16691 16559 16509 16492>,
			<17152 16747 16680 16564 16517 16497>,
			<17170 16763 16654 16572 16529 16508>,
			<17187 16795 16630 16579 16543 16520>,
			<17201 16852 16619 16590 16558 16534>,
			<17212 16954 16610 16599 16572 16547>,
			<17223 17035 16609 16598 16575 16552>,
			<17236 17084 16632 16587 16574 16554>,
			<17251 17121 16671 16574 16572 16555>,
			<17268 17144 16715 16562 16545 16530>,
			<17289 17163 16772 16553 16504 16491>,
			<17314 17170 16819 16551 16497 16484>,
			<17342 17171 16854 16554 16502 16488>,
			<17376 17170 16883 16557 16506 16490>,
			<17412 17169 16906 16565 16506 16489>,
			<17457 17166 16927 16571 16506 16486>,
			<17483 17172 16959 16563 16497 16479>,
			<17499 17200 17007 16573 16498 16483>,
			<17497 17244 17041 16585 16512 16496>,
			<17455 17207 17022 16607 16521 16496>,
			<17351 17247 17091 16628 16533 16501>,
			<17383 17298 17177 16673 16535 16496>,
			<17478 17344 17262 16678 16514 16490>,
			<17819 17317 17239 16697 16536 16513>,
			<18870 17370 17219 16807 16598 16566>,
			<22689 18164 17277 17003 16769 16714>,
			<53082 38546 17646 17434 17224 17156>,
			<53082 38546 17646 17434 17224 17156>,
			<53082 38546 17646 17434 17224 17156>;
	};

	qcom,pc-temp-y5-lut {
		qcom,lut-col-legend = <(-10) 0 10 25 40 50>;
		qcom,lut-row-legend = <10000 9800 9600 9400 9200 9000>,
			<8800 8600 8400 8200 8000 7800>,
			<7600 7400 7200 7000 6800 6600>,
			<6400 6200 6000 5800 5600 5400>,
			<5200 5000 4800 4600 4400 4200>,
			<4000 3800 3600 3400 3200 3000>,
			<2800 2600 2400 2200 2000 1800>,
			<1600 1400 1200 1000 900 800>,
			<700 600 500 400 300 200>,
			<100 0>;
		qcom,lut-data = <12011 12451 13144 12912 16172 12866>,
			<12053 12556 13314 13377 14900 13260>,
			<12214 12684 13433 13621 13888 13500>,
			<12473 12817 13508 13697 13148 13625>,
			<12811 12934 13542 13658 12693 13673>,
			<13209 13018 13542 13553 12538 13680>,
			<13804 13063 13498 13237 13143 13612>,
			<14451 13106 13416 12815 14089 13461>,
			<14513 13232 13314 12659 14233 13270>,
			<13539 13672 13143 12610 13967 12972>,
			<12685 13995 12979 12544 13633 12809>,
			<13381 13771 12857 12276 13291 13265>,
			<15081 13323 12759 11943 12924 13971>,
			<15664 13276 12763 11941 12596 14021>,
			<15033 14022 12984 12255 12259 13523>,
			<14360 14749 13321 12478 12095 13006>,
			<14186 14918 13841 12500 12387 12610>,
			<13978 15008 14547 12514 12925 12297>,
			<14067 15153 15023 12728 13222 12302>,
			<14775 15443 15372 13748 13375 12654>,
			<15484 15707 15569 14597 13568 13124>,
			<14892 15808 15567 14971 14076 13820>,
			<12375 15868 15524 15251 14720 14524>,
			<10923 15968 15535 15285 15036 14635>,
			<10860 16256 15705 15227 15225 14562>,
			<10851 16505 15939 15189 15305 14498>,
			<10870 15628 16208 15184 15163 14611>,
			<10940 13097 16546 15200 14859 14801>,
			<10991 11992 16717 15276 14552 14769>,
			<11009 12112 16699 15435 14165 14510>,
			<11033 12258 16568 15669 13956 14348>,
			<11062 12098 16209 16278 14313 14497>,
			<11100 11581 15597 16998 15055 14811>,
			<11135 11331 15327 17098 15705 15161>,
			<11164 11391 15401 16926 16397 15700>,
			<11189 11508 15495 16814 16754 15998>,
			<11200 11676 15410 16956 16659 15800>,
			<11202 11944 15166 17177 16441 15396>,
			<11200 12097 14873 17181 16187 14999>,
			<11199 12132 14453 16918 15733 14490>,
			<11199 12151 14007 16554 15373 14222>,
			<11217 12099 13687 15679 15212 14261>,
			<11317 11870 13354 14975 15115 14364>,
			<11450 11793 12468 15669 14746 15050>,
			<11607 11772 11558 15159 15047 15054>,
			<11838 11599 11443 14556 15091 14560>,
			<11848 11583 11494 14890 14248 15509>,
			<11845 11715 11350 14464 13906 14936>,
			<11944 11976 11374 14427 13909 16289>,
			<11985 12274 11341 14689 16156 14988>,
			<11182 12226 11576 15836 17669 18378>,
			<10237 11571 11535 16284 17610 18021>,
			<9472 11252 11619 16291 17745 17777>,
			<9009 9878 11607 15815 17218 17368>,
			<9009 9878 11607 15815 17218 17368>,
			<9009 9878 11607 15815 17218 17368>;
	};

	qcom,pc-temp-y6-lut {
		qcom,lut-col-legend = <(-10) 0 10 25 40 50>;
		qcom,lut-row-legend = <10000 9800 9600 9400 9200 9000>,
			<8800 8600 8400 8200 8000 7800>,
			<7600 7400 7200 7000 6800 6600>,
			<6400 6200 6000 5800 5600 5400>,
			<5200 5000 4800 4600 4400 4200>,
			<4000 3800 3600 3400 3200 3000>,
			<2800 2600 2400 2200 2000 1800>,
			<1600 1400 1200 1000 900 800>,
			<700 600 500 400 300 200>,
			<100 0>;
		qcom,lut-data = <6946 5836 5331 5079 5010 4989>,
			<6964 5847 5335 5081 5010 4990>,
			<6992 5866 5339 5083 5010 4990>,
			<7022 5887 5344 5085 5010 4991>,
			<7047 5904 5347 5086 5011 4992>,
			<7059 5913 5350 5088 5012 4992>,
			<7059 5915 5351 5089 5014 4994>,
			<7056 5916 5352 5091 5016 4995>,
			<7047 5917 5353 5093 5018 4996>,
			<6993 5920 5355 5095 5020 4998>,
			<6945 5922 5358 5097 5022 5000>,
			<6947 5922 5361 5100 5024 5002>,
			<6958 5923 5366 5104 5027 5005>,
			<6955 5920 5373 5108 5029 5008>,
			<6870 5908 5387 5114 5032 5010>,
			<6772 5889 5397 5121 5035 5013>,
			<6737 5866 5398 5128 5040 5015>,
			<6718 5839 5398 5136 5046 5019>,
			<6700 5817 5395 5146 5054 5024>,
			<6681 5801 5379 5160 5066 5033>,
			<6660 5786 5358 5168 5073 5038>,
			<6631 5767 5337 5142 5057 5028>,
			<6590 5745 5314 5101 5030 5010>,
			<6572 5723 5301 5085 5019 5001>,
			<6606 5699 5294 5078 5013 4994>,
			<6676 5678 5290 5076 5010 4991>,
			<6752 5666 5288 5076 5011 4992>,
			<6848 5655 5286 5078 5013 4994>,
			<6950 5652 5284 5079 5014 4996>,
			<7054 5681 5277 5082 5017 4999>,
			<7158 5732 5271 5085 5020 5002>,
			<7251 5790 5269 5089 5026 5007>,
			<7336 5868 5269 5092 5031 5011>,
			<7413 5951 5272 5092 5033 5013>,
			<7484 6038 5287 5087 5032 5013>,
			<7549 6129 5312 5084 5031 5013>,
			<7611 6220 5341 5082 5023 5005>,
			<7669 6312 5376 5082 5010 4991>,
			<7726 6412 5413 5082 5008 4989>,
			<7787 6520 5448 5085 5010 4990>,
			<7849 6641 5486 5088 5012 4991>,
			<7918 6783 5528 5091 5013 4992>,
			<7994 6951 5577 5094 5014 4992>,
			<8091 7135 5637 5096 5010 4990>,
			<8231 7330 5721 5102 5011 4992>,
			<8456 7508 5815 5107 5019 4999>,
			<8494 7480 5806 5120 5023 5003>,
			<8513 7638 5923 5132 5028 5006>,
			<8829 7824 6087 5154 5030 5007>,
			<9356 8040 6275 5163 5027 5000>,
			<10455 8311 6524 5183 5037 5013>,
			<12708 8968 6925 5244 5060 5031>,
			<17334 11326 7502 5346 5116 5077>,
			<29965 19932 8546 5575 5256 5212>,
			<29965 19932 8546 5575 5256 5212>,
			<29965 19932 8546 5575 5256 5212>;
	};

};
